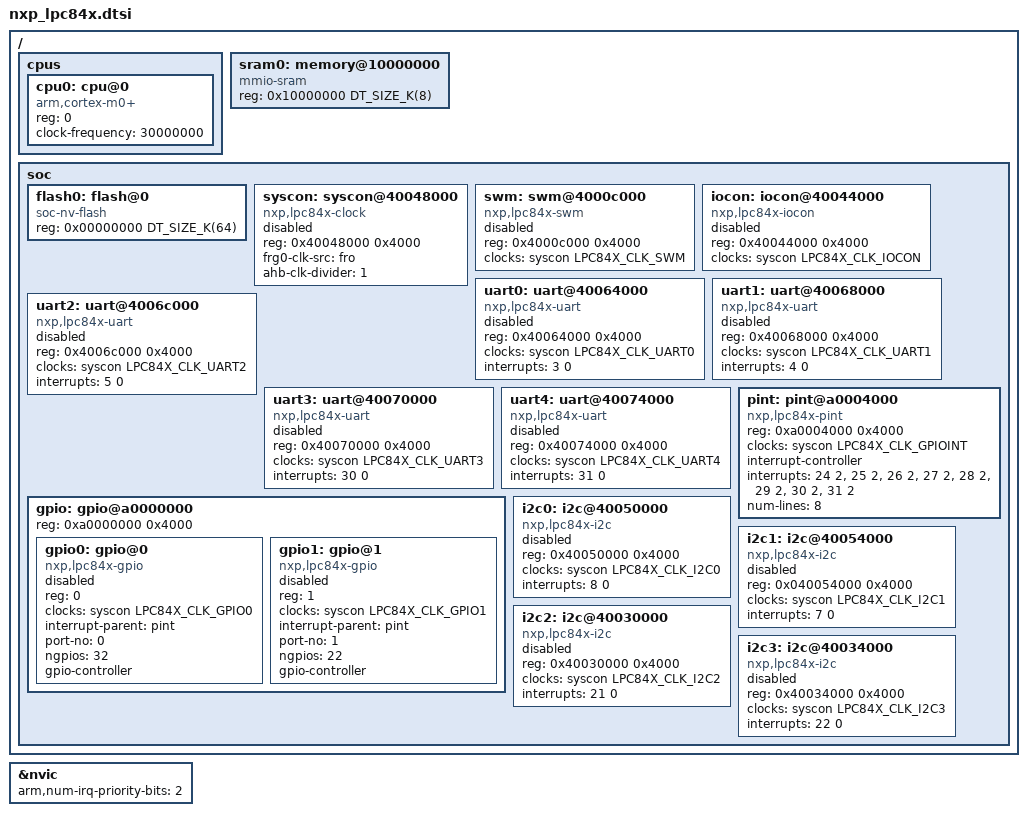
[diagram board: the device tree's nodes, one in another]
/*
 * Copyright (c) 2026 Aerlync Labs Inc.
 *
 * SPDX-License-Identifier: Apache-2.0
 */

#include <arm/armv6-m.dtsi>
#include <mem.h>
#include <zephyr/dt-bindings/clock/lpc84x-clock.h>

/ {
	cpus {
		#address-cells = <1>;
		#size-cells = <0>;

		cpu0: cpu@0 {
			compatible = "arm,cortex-m0+";
			reg = <0>;
			clock-frequency = <30000000>;
		};
	};

	/*
	 * LPC84X have either 8KB or 16KB of SRAM
	 * that should be taken care in board specific .dtsi
	 */

	sram0: memory@10000000 {
		compatible = "mmio-sram";
		reg = <0x10000000 DT_SIZE_K(8)>;
	};

	soc {
		flash0: flash@0 {
			compatible = "soc-nv-flash";
			reg = <0x00000000 DT_SIZE_K(64)>;
		};

		syscon: syscon@40048000 {
			compatible = "nxp,lpc84x-clock";
			reg = <0x40048000 0x4000>;
			#clock-cells = <1>;
			frg0-clk-src = "fro";
			ahb-clk-divider = <1>;
			status = "disabled";
		};

		swm: swm@4000c000 {
			compatible = "nxp,lpc84x-swm";
			reg = <0x4000c000 0x4000>;
			clocks = <&syscon LPC84X_CLK_SWM>;
			status = "disabled";
		};

		iocon: iocon@40044000 {
			compatible = "nxp,lpc84x-iocon";
			reg = <0x40044000 0x4000>;
			clocks = <&syscon LPC84X_CLK_IOCON>;
			status = "disabled";
		};

		uart0: uart@40064000 {
			compatible = "nxp,lpc84x-uart";
			reg = <0x40064000 0x4000>;
			clocks = <&syscon LPC84X_CLK_UART0>;
			interrupts = <3 0>;
			status = "disabled";
		};

		uart1: uart@40068000 {
			compatible = "nxp,lpc84x-uart";
			reg = <0x40068000 0x4000>;
			clocks = <&syscon LPC84X_CLK_UART1>;
			interrupts = <4 0>;
			status = "disabled";
		};

		uart2: uart@4006c000 {
			compatible = "nxp,lpc84x-uart";
			reg = <0x4006c000 0x4000>;
			clocks = <&syscon LPC84X_CLK_UART2>;
			interrupts = <5 0>;
			status = "disabled";
		};

		uart3: uart@40070000 {
			compatible = "nxp,lpc84x-uart";
			reg = <0x40070000 0x4000>;
			clocks = <&syscon LPC84X_CLK_UART3>;
			interrupts = <30 0>;
			status = "disabled";
		};

		uart4: uart@40074000 {
			compatible = "nxp,lpc84x-uart";
			reg = <0x40074000 0x4000>;
			clocks = <&syscon LPC84X_CLK_UART4>;
			interrupts = <31 0>;
			status = "disabled";
		};

		gpio: gpio@a0000000 {
			reg = <0xa0000000 0x4000>;
			#address-cells = <1>;
			#size-cells = <0>;

			gpio0: gpio@0 {
				compatible = "nxp,lpc84x-gpio";
				reg = <0>;
				clocks = <&syscon LPC84X_CLK_GPIO0>;
				interrupt-parent = <&pint>;
				port-no = <0>;
				ngpios = <32>;
				gpio-controller;
				#gpio-cells = <2>;
				status = "disabled";
			};

			gpio1: gpio@1 {
				compatible = "nxp,lpc84x-gpio";
				reg = <1>;
				clocks = <&syscon LPC84X_CLK_GPIO1>;
				interrupt-parent = <&pint>;
				port-no = <1>;
				ngpios = <22>;
				gpio-controller;
				#gpio-cells = <2>;
				status = "disabled";
			};
		};

		pint: pint@a0004000 {
			compatible = "nxp,lpc84x-pint";
			reg = <0xa0004000 0x4000>;
			clocks = <&syscon LPC84X_CLK_GPIOINT>;
			interrupt-controller;
			#interrupt-cells = <1>;
			#address-cells = <0>;
			interrupts = <24 2>, <25 2>, <26 2>, <27 2>,
				     <28 2>, <29 2>, <30 2>, <31 2>;
			num-lines = <8>;
		};

		i2c0: i2c@40050000 {
			compatible = "nxp,lpc84x-i2c";
			reg = <0x40050000 0x4000>;
			clocks = <&syscon LPC84X_CLK_I2C0>;
			#address-cells = <1>;
			#size-cells = <0>;
			interrupts = <8 0>;
			status = "disabled";
		};

		i2c1: i2c@40054000 {
			compatible = "nxp,lpc84x-i2c";
			reg = <0x040054000 0x4000>;
			clocks = <&syscon LPC84X_CLK_I2C1>;
			#address-cells = <1>;
			#size-cells = <0>;
			interrupts = <7 0>;
			status = "disabled";
		};

		i2c2: i2c@40030000 {
			compatible = "nxp,lpc84x-i2c";
			reg = <0x40030000 0x4000>;
			clocks = <&syscon LPC84X_CLK_I2C2>;
			#address-cells = <1>;
			#size-cells = <0>;
			interrupts = <21 0>;
			status = "disabled";
		};

		i2c3: i2c@40034000 {
			compatible = "nxp,lpc84x-i2c";
			reg = <0x40034000 0x4000>;
			clocks = <&syscon LPC84X_CLK_I2C3>;
			#address-cells = <1>;
			#size-cells = <0>;
			interrupts = <22 0>;
			status = "disabled";
		};
	};
};

&nvic {
	arm,num-irq-priority-bits = <2>;
};
